# STM32WL33 register map
File version: 1.0
CPU: CM0+ r0p0, little endian, MPU, no FPU, 4 interrupt priority bits
Registers are 32-bit, read-write, reset 0x0 unless marked. A register's access mark holds for its fields unless they carry their own. Offsets are from the block's base; [hi:lo] are bit positions.

## LCSC
Base 0x4000A000
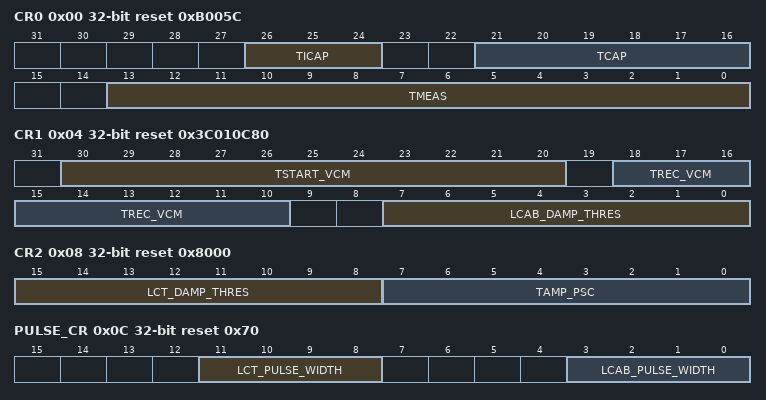
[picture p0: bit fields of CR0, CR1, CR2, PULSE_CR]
0x00 CR0 reset 0xB005C — LCSC_CR0 register
  [26:24] TICAP — Inter Capture Time
  [21:16] TCAP — Capture Time
  [13:0] TMEAS — Measurement Time
0x04 CR1 reset 0x3C010C80 — LCSC_CR1 register
  [30:20] TSTART_VCM — VCMBUFF Starting Time
  [18:10] TREC_VCM — VCMBUFF Recovery Time
  [7:0] LCAB_DAMP_THRES — LCAB_DAMP_THRES[7:0]: Damping threshold for LCA and LCB
0x08 CR2 reset 0x8000 — LCSC_CR2 register
  [15:8] LCT_DAMP_THRES — Damping threshold for LCT
  [7:0] TAMP_PSC — Tamper measurement interval.
0x0C PULSE_CR reset 0x70 — LCSC_PULSE_CR register
  [11:8] LCT_PULSE_WIDTH — Low Pulse Width for LCT
  [3:0] LCAB_PULSE_WIDTH — Low Pulse Width for LCA and LCB
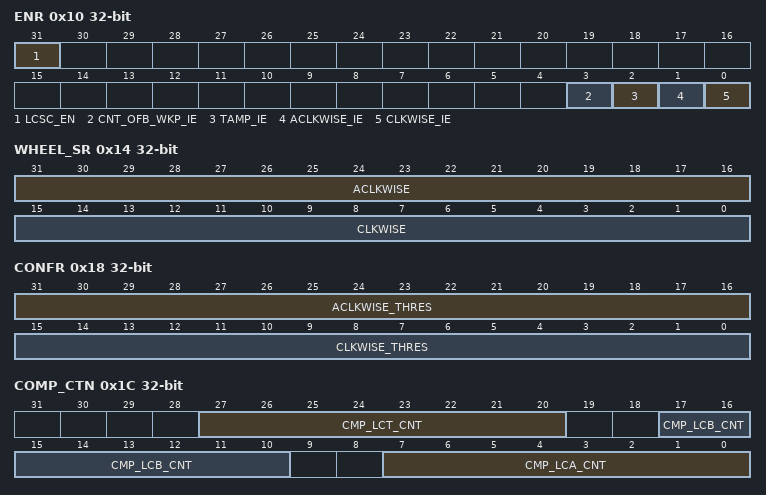
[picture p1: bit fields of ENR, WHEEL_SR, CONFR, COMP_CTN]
0x10 ENR — LCSC_ENR register
  [31] LCSC_EN — LCSC Enable
  [3] CNT_OFB_WKP_IE — LCAB Counter Out Of Bound wakeup enable
  [2] TAMP_IE — Tamper Interrupt and Wakeup Enable
  [1] ACLKWISE_IE — Anti Clock Wise Interrupt and Wakeup Enable
  [0] CLKWISE_IE — Clock Wise Interrupt and Wakeup Enable
0x14 WHEEL_SR ro — LCSC_WHEEL_SR register
  [31:16] ACLKWISE — Number of Anti Clock Wise revolutions
  [15:0] CLKWISE — Number of Clock Wise revolutions
0x18 CONFR — LCSC_CONFR register
  [31:16] ACLKWISE_THRES — Number of Anti Clock Wise revolutions target
  [15:0] CLKWISE_THRES — Number of Clock Wise revolutions target
0x1C COMP_CTN ro — LCSC_COMP_CTN register
  [27:20] CMP_LCT_CNT — LCT Comparator last damping count
  [17:10] CMP_LCB_CNT — LCB Comparator last damping count
  [7:0] CMP_LCA_CNT — LCA Comparator last damping count
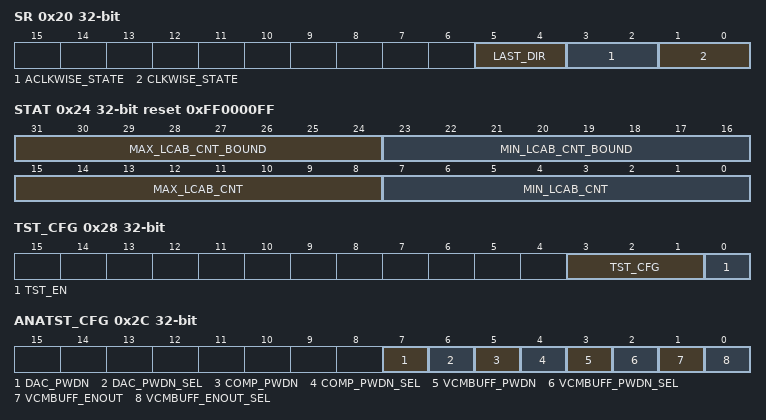
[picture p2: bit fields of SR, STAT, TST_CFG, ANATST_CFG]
0x20 SR ro — LCSC_SR register
  [5:4] LAST_DIR — The last direction detected:
  [3:2] ACLKWISE_STATE — The current state of the LCSC anti clockwise FSM:
  [1:0] CLKWISE_STATE — The current state of the LCSC clockwise FSM:
0x24 STAT reset 0xFF0000FF — LCSC_STAT register
  [31:24] MAX_LCAB_CNT_BOUND — The Maximum bound of CMP_LCA_COUNT,
  [23:16] MIN_LCAB_CNT_BOUND — The Minimum bound of CMP_LCA_COUNT,
  [15:8] MAX_LCAB_CNT ro — The Maximum of CMP_LCA_CNT, CMP_LCB_CNT reached during
  [7:0] MIN_LCAB_CNT ro — The Minimum of CMP_LCA_CNT, CMP_LCB_CNT reached during the
0x28 TST_CFG — LCSC Test Configuration Register
  [3:1] TST_CFG — DTB output selection
  [0] TST_EN — Test Enable
0x2C ANATST_CFG — LCSC ANA Test Configuration Register
  [7] DAC_PWDN — DAC power-down pin
  [6] DAC_PWDN_SEL — Selection of the signal to be used to supply the DAC in the LCSC Analog part
  [5] COMP_PWDN — COMP power-down pin
  [4] COMP_PWDN_SEL — Selection of the signal to be used to supply the COMP in the LCSC Analog part
  [3] VCMBUFF_PWDN — VCMBUFF power-down pin
  [2] VCMBUFF_PWDN_SEL — Selection of the signal to be used to supply the DAC in the LCSC
  [1] VCMBUFF_ENOUT — VCMBUFFER output buffer enable pin
  [0] VCMBUFF_ENOUT_SEL — Selection of the signal to be used to supply the DAC in the LCSC
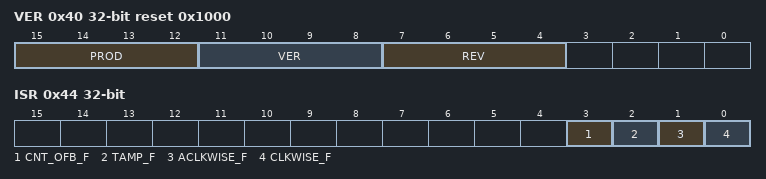
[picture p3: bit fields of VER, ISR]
0x40 VER ro reset 0x1000 — LCSC_VER register
  [15:12] PROD — Used for major upgrades (new protocols support / new features)
  [11:8] VER — Version of the RFIP (to be used for cut upgrades)
  [7:4] REV — Revision of the RFIP to be used for metal fixes)
0x44 ISR — LCSC_ISR register
  [3] CNT_OFB_F — Out of Bound Counter Flag
  [2] TAMP_F — Tamper Flag
  [1] ACLKWISE_F — Anti Clock Wise Flag:
  [0] CLKWISE_F — Clock Wise Flag:

## LPAWUR
Base 0x49001000
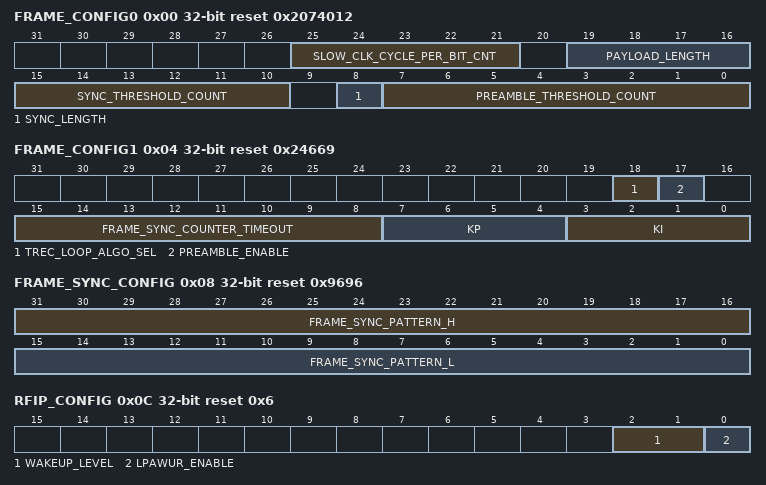
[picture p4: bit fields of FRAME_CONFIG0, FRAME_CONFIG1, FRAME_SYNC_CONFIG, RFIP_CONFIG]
0x00 FRAME_CONFIG0 reset 0x2074012
  [25:21] SLOW_CLK_CYCLE_PER_BIT_CNT — The number of expected slow clock cycle per each manchester coded bit.
  [19:16] PAYLOAD_LENGTH — The number of data Bytes in the payload ( decoded ).
  [15:10] SYNC_THRESHOLD_COUNT — detection threshold when receivng the Frame sync ( Manchester encoded).
  [8] SYNC_LENGTH — Frame sync pattern length ( Manchester encoded ).
  [7:0] PREAMBLE_THRESHOLD_COUNT — The number of transitions for preamble detection when receiving the manchester encoded preamble.
0x04 FRAME_CONFIG1 reset 0x24669
  [18] TREC_LOOP_ALGO_SEL — Timing recovery loop algorithm selection:
  [17] PREAMBLE_ENABLE — Preamble detection enable
  [15:8] FRAME_SYNC_COUNTER_TIMEOUT — The timeout in manchester encoded bits for the Frame Sync,it represents the number of samples after which in case the frame sync is not detected a sync_error is raised.
  [7:4] KP — kp gain value for the timing recovery loop.
  [3:0] KI — ki gain value for the timing recovery loop.
0x08 FRAME_SYNC_CONFIG reset 0x9696
  [31:16] FRAME_SYNC_PATTERN_H — The value of the frame sync pattern, High word, manchester encoded, used only when the frame sync length is 32 bits (default 0x0000 )
  [15:0] FRAME_SYNC_PATTERN_L — The value of the frame sync pattern, Low word, manchester encoded, used when the frame sync length is 16 bit (default 0x9696 which represent a frame sync value of 0x99)
0x0C RFIP_CONFIG reset 0x6
  [2:1] WAKEUP_LEVEL — - 00: the bit Sync has been detected
  [0] LPAWUR_ENABLE — Enable (start) or Disable (stop) the LPAWUR feature (0: disabled by default)
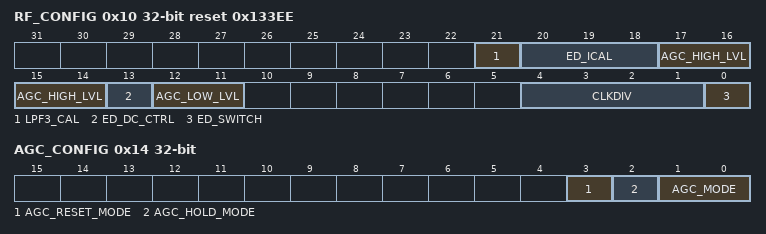
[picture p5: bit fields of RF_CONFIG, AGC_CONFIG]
0x10 RF_CONFIG reset 0x133EE
  [21] LPF3_CAL
  [20:18] ED_ICAL — Current versus VBAT calibration for ED
  [17:14] AGC_HIGH_LVL — AGC level (High) (default value: 0x4)
  [13] ED_DC_CTRL — DC current subtraction enabling signal (default value: 0x1)
  [12:11] AGC_LOW_LVL — AGC level (Low) (default value: 0x2)
  [4:1] CLKDIV — Calibrate 4kHz clock (programmable divider)
  [0] ED_SWITCH — - 0 : Normal operation (default)
0x14 AGC_CONFIG
  [3] AGC_RESET_MODE — The AGC reset behavior when the AGC is working in ON or HOLD mode
  [2] AGC_HOLD_MODE — The behavior when the AGC is ON and is working in HOLD mode
  [1:0] AGC_MODE — Define the working mode of the AGC:
0x1C PAYLOAD_0 ro
  [31:0] PAYLOAD_0 — First part of the payload (Least significant Byte First)
0x20 PAYLOAD_1 ro
  [31:0] PAYLOAD_1 — Second part of the payload (Least significant Byte First)
